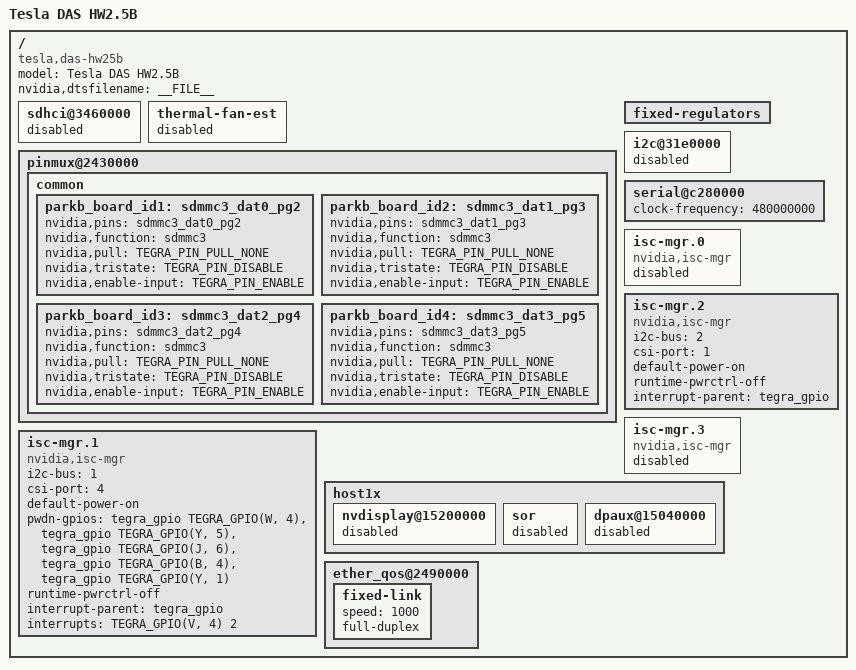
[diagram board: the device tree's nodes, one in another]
/*
 * tegra186-tesla-hw25b: DTS for HW2.5B (Backup Parker)
 *
 * Copyright (c) 2017, Tesla Motors.  All rights reserved.
 *
 * Based on Drive PX2 DTS files:
 *
 * Copyright (c) 2016, NVIDIA CORPORATION.  All rights reserved.
 *
 * This program is free software; you can redistribute it and/or modify
 * it under the terms of the GNU General Public License as published by
 * the Free Software Foundation; version 2 of the License.
 *
 * This program is distributed in the hope that it will be useful, but WITHOUT
 * ANY WARRANTY; without even the implied warranty of MERCHANTABILITY or
 * FITNESS FOR A PARTICULAR PURPOSE.  See the GNU General Public License for
 * more details.
*/

#include "tegra186-tesla-das-hw20-rev-c.dts"

/ {
	model = "Tesla DAS HW2.5B";
	compatible = "tesla,das-hw25b", "nvidia,tegra186";

	nvidia,dtsfilename = __FILE__;

	sdhci@3460000 {
		status = "disabled";
	};

	/delete-node/thermal-fan-est;
	thermal-fan-est {
		status = "disabled";
	};

	pinmux@2430000 {
		common {
			/*
			 * BOARD Revision ID Straps. Pinmux in the
			 * bootchain has these pins pulled down and disabled.
			 * Enable them here.
			 */
			parkb_board_id1: sdmmc3_dat0_pg2 {
				nvidia,pins = "sdmmc3_dat0_pg2";
				nvidia,function = "sdmmc3";
				nvidia,pull = <TEGRA_PIN_PULL_NONE>;
				nvidia,tristate = <TEGRA_PIN_DISABLE>;
				nvidia,enable-input = <TEGRA_PIN_ENABLE>;
			};
			parkb_board_id2: sdmmc3_dat1_pg3 {
				nvidia,pins = "sdmmc3_dat1_pg3";
				nvidia,function = "sdmmc3";
				nvidia,pull = <TEGRA_PIN_PULL_NONE>;
				nvidia,tristate = <TEGRA_PIN_DISABLE>;
				nvidia,enable-input = <TEGRA_PIN_ENABLE>;
			};
			parkb_board_id3: sdmmc3_dat2_pg4 {
				nvidia,pins = "sdmmc3_dat2_pg4";
				nvidia,function = "sdmmc3";
				nvidia,pull = <TEGRA_PIN_PULL_NONE>;
				nvidia,tristate = <TEGRA_PIN_DISABLE>;
				nvidia,enable-input = <TEGRA_PIN_ENABLE>;
			};
			parkb_board_id4: sdmmc3_dat3_pg5 {
				nvidia,pins = "sdmmc3_dat3_pg5";
				nvidia,function = "sdmmc3";
				nvidia,pull = <TEGRA_PIN_PULL_NONE>;
				nvidia,tristate = <TEGRA_PIN_DISABLE>;
				nvidia,enable-input = <TEGRA_PIN_ENABLE>;
			};

		};
	};

	fixed-regulators {
		/delete-node/regulator@99; /* PARK-TIMEPULSE-EN */
	};

	/* No gpu temp sensor */
	i2c@31e0000 {
		status = "disabled";
	};

	serial@c280000 { /* Tegra UARTC <-> Aurix UART: Debug console  */
		/* to maintain 115200 baud, clock frequency changed with 480MHz */
		clock-frequency = <480000000>;
	};

	/delete-node/isc-mgr.0;
	/delete-node/isc-mgr.1;
	/delete-node/isc-mgr.2;
	/delete-node/isc-mgr.3;

	isc-mgr.0 {
		compatible = "nvidia,isc-mgr";
		status = "disabled";
	};
	/* CSI-EF */
	isc-mgr.1 {
		compatible = "nvidia,isc-mgr";
		i2c-bus = <1>;
		csi-port = <4>;
		default-power-on;
		pwdn-gpios = < &tegra_gpio TEGRA_GPIO(W, 4) GPIO_ACTIVE_HIGH   /* QD2-PWR-DOWN */
			&tegra_gpio TEGRA_GPIO(Y, 5) GPIO_ACTIVE_HIGH   /* PARK-MAIN-CAM-PWR-EN - TegraBall(PY.05) */
			&tegra_gpio TEGRA_GPIO(J, 6) GPIO_ACTIVE_HIGH   /* PARK-RR-CAM-PWR-EN - TegraBall(PJ.06) */
			&tegra_gpio TEGRA_GPIO(B, 4) GPIO_ACTIVE_HIGH   /* PARK-FE-CAM-PWR-EN - Tegra(PB.04)  */
			&tegra_gpio TEGRA_GPIO(Y, 1) GPIO_ACTIVE_HIGH   /* PARK-LR-CAM-PWR-EN - TegraBall(PY.01) */ >;
		runtime-pwrctrl-off;
		interrupt-parent = <&tegra_gpio>;
		interrupts = <TEGRA_GPIO(V, 4) 2>; /* QD2-LOCK : falling edge sensitive */
		status = "okay";
	};
	/* CSI-B */
	isc-mgr.2 {
		compatible = "nvidia,isc-mgr";
		i2c-bus = <2>;
		csi-port = <1>;
		default-power-on;
		runtime-pwrctrl-off;
		interrupt-parent = <&tegra_gpio>;
		status = "okay";
	};
	isc-mgr.3 {
		compatible = "nvidia,isc-mgr";
		status = "disabled";
	};

	host1x {
		nvdisplay@15200000 {
			status = "disabled";
		};

		sor {
			status = "disabled";
		};

		dpaux@15040000 {
			status = "disabled";
		};
	};

	ether_qos@2490000 {
		fixed-link{
			speed = <1000>;
			full-duplex;
		};
	};
};
